CM_ "IMPORT _honda_common_c2_mdx.dbc";
CM_ "IMPORT _bosch_2018.dbc";

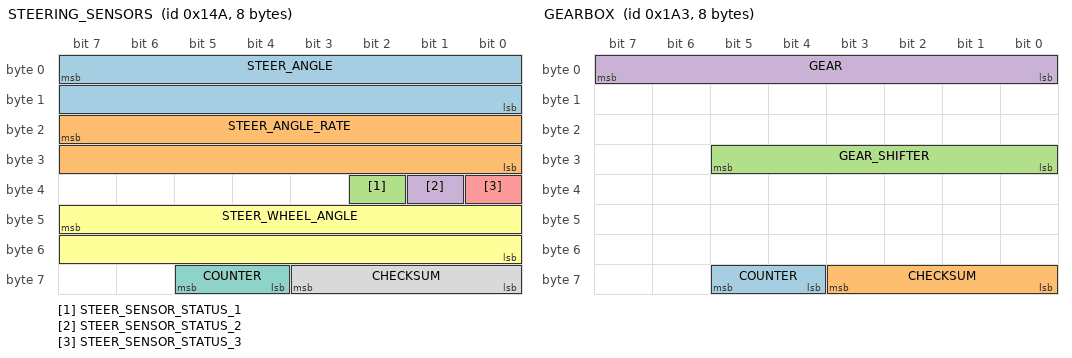
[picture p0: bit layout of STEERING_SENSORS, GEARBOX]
BO_ 330 STEERING_SENSORS: 8 EPS
 SG_ STEER_ANGLE : 7|16@0- (-0.1,0) [-500|500] "deg" EON
 SG_ STEER_ANGLE_RATE : 23|16@0- (-1,0) [-3000|3000] "deg/s" EON
 SG_ STEER_SENSOR_STATUS_1 : 34|1@0+ (1,0) [0|1] "" EON
 SG_ STEER_SENSOR_STATUS_2 : 33|1@0+ (1,0) [0|1] "" EON
 SG_ STEER_SENSOR_STATUS_3 : 32|1@0+ (1,0) [0|1] "" EON
 SG_ STEER_WHEEL_ANGLE : 47|16@0- (-0.1,0) [-500|500] "deg" EON
 SG_ COUNTER : 61|2@0+ (1,0) [0|3] "" EON
 SG_ CHECKSUM : 59|4@0+ (1,0) [0|15] "" EON

BO_ 419 GEARBOX: 8 PCM
 SG_ COUNTER : 61|2@0+ (1,0) [0|3] "" EON
 SG_ CHECKSUM : 59|4@0+ (1,0) [0|3] "" EON
 SG_ GEAR_SHIFTER : 29|6@0+ (1,0) [0|63] "" EON
 SG_ GEAR : 7|8@0+ (1,0) [0|255] "" EON

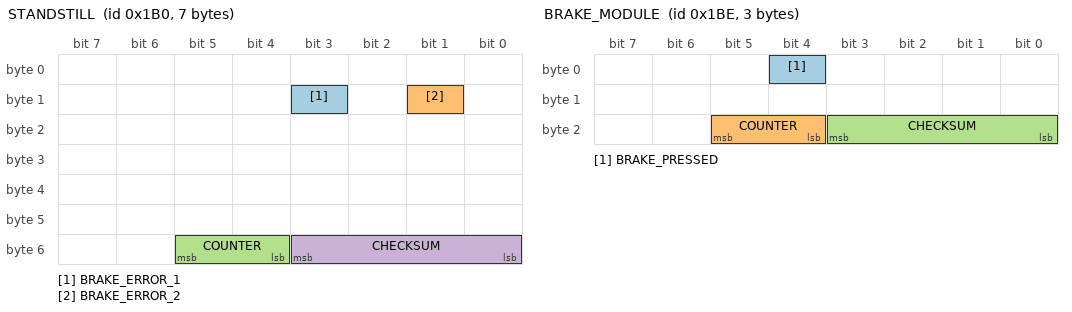
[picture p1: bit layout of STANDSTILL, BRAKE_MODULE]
BO_ 432 STANDSTILL: 7 VSA
 SG_ BRAKE_ERROR_1 : 11|1@0+ (1,0) [0|1] "" EON
 SG_ BRAKE_ERROR_2 : 9|1@0+ (1,0) [0|1] "" EON
 SG_ COUNTER : 53|2@0+ (1,0) [0|3] "" EON
 SG_ CHECKSUM : 51|4@0+ (1,0) [0|15] "" EON

BO_ 446 BRAKE_MODULE: 3 VSA
 SG_ BRAKE_PRESSED : 4|1@0+ (1,0) [0|1] "" XXX
 SG_ COUNTER : 21|2@0+ (1,0) [0|3] "" XXX
 SG_ CHECKSUM : 19|4@0+ (1,0) [0|15] "" XXX

BO_ 829 LKAS_HUD: 8 XXX
 SG_ SET_ME_X41 : 6|7@0+ (1,0) [0|127] "" XXX
 SG_ BOH : 6|7@0+ (1,0) [0|127] "" XXX
 SG_ CAM_TEMP_HIGH : 7|1@0+ (1,0) [0|255] "" XXX
 SG_ STEERING_REQUIRED : 8|1@0+ (1,0) [0|1] "" XXX
 SG_ LDW_RIGHT : 9|1@0+ (1,0) [0|1] "" XXX
 SG_ SOLID_LANES : 10|1@0+ (1,0) [0|1] "" XXX
 SG_ LKAS_OFF : 11|1@0+ (1,0) [0|1] "" XXX
 SG_ LKAS_PROBLEM : 12|1@0+ (1,0) [0|1] "" XXX
 SG_ DTC : 13|1@0+ (1,0) [0|1] "" XXX
 SG_ DASHED_LANES : 14|1@0+ (1,0) [0|1] "" XXX
 SG_ BEEP : 17|2@0+ (1,0) [0|1] "" XXX
 SG_ LDW_PROBLEM : 21|1@0+ (1,0) [0|1] "" XXX
 SG_ BOH_2 : 23|2@0+ (1,0) [0|4] "" XXX
 SG_ CLEAN_WINDSHIELD : 26|1@0+ (1,0) [0|1] "" XXX
 SG_ LDW_OFF : 27|1@0+ (1,0) [0|1] "" XXX
 SG_ LDW_ON : 28|1@0+ (1,0) [0|1] "" XXX
 SG_ SET_ME_X48 : 31|8@0+ (1,0) [0|255] "" XXX
 SG_ LANE_LINES : 36|2@0+ (1,0) [0|3] "" XXX
 SG_ CHECKSUM : 59|4@0+ (1,0) [0|15] "" XXX
 SG_ COUNTER : 61|2@0+ (1,0) [0|3] "" XXX

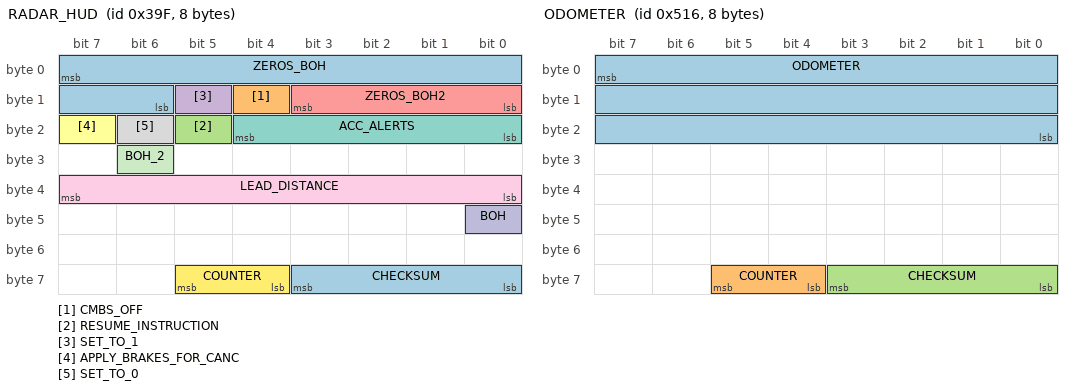
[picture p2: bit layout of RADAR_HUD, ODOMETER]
BO_ 927 RADAR_HUD: 8 RADAR
 SG_ ZEROS_BOH : 7|10@0+ (1,0) [0|127] "" BDY
 SG_ CMBS_OFF : 12|1@0+ (1,0) [0|1] "" BDY
 SG_ RESUME_INSTRUCTION : 21|1@0+ (1,0) [0|1] "" XXX
 SG_ SET_TO_1 : 13|1@0+ (1,0) [0|1] "" BDY
 SG_ ZEROS_BOH2 : 11|4@0+ (1,0) [0|1] "" XXX
 SG_ APPLY_BRAKES_FOR_CANC : 23|1@0+ (1,0) [0|1] "" XXX
 SG_ ACC_ALERTS : 20|5@0+ (1,0) [0|1] "" BDY
 SG_ SET_TO_0 : 22|1@0+ (1,0) [0|1] "" XXX
 SG_ LEAD_DISTANCE : 39|8@0+ (1,0) [0|255] "" XXX
 SG_ BOH : 40|1@0+ (1,0) [0|1] "" XXX
 SG_ BOH_2 : 30|1@0+ (1,0) [0|1] "" XXX
 SG_ COUNTER : 61|2@0+ (1,0) [0|3] "" XXX
 SG_ CHECKSUM : 59|4@0+ (1,0) [0|15] "" XXX

BO_ 1302 ODOMETER: 8 XXX
 SG_ ODOMETER : 7|24@0+ (1,0) [0|16777215] "km" EON
 SG_ COUNTER : 61|2@0+ (1,0) [0|3] "" EON
 SG_ CHECKSUM : 59|4@0+ (1,0) [0|3] "" EON

VAL_ 419 GEAR_SHIFTER  32 "D" 8 "R" 4 "P" ;
VAL_ 545 ECON_ON_2 0 "off" 3 "on" ;
VAL_ 662 CRUISE_BUTTONS 7 "tbd" 6 "tbd" 5 "tbd" 4 "accel_res" 3 "decel_set" 2 "cancel" 1 "main" 0 "none" ;
VAL_ 662 CRUISE_SETTING 3 "distance_adj" 2 "tbd" 1 "lkas_button" 0 "none" ;
VAL_ 806 CMBS_BUTTON 3 "pressed" 0 "released" ;

CM_ SG_ 829 BEEP "beeps are pleasant, chimes are for warnings etc...";
CM_ SG_ 829 LANE_LINES "related to lane lines on cluster, left/right white/green";

VAL_ 829 BEEP 5 "solid_beep" 4 "double_beep" 3 "single_beep" 2 "triple_beep" 1 "repeated_beep" 0 "no_beep";
VAL_ 829 LANE_LINES 7 "both_lines_green" 6 "both_lines_white" 2 "left_line_white" 0 "no_lines";
